AUTOSAR XML (schema 4-2-2)
package /COM_SWC
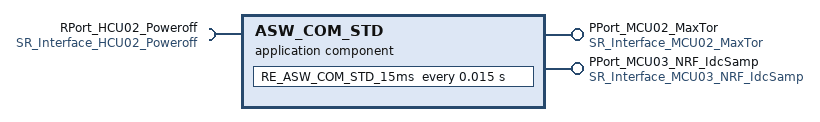
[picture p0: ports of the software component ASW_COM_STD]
  application sw component type ASW_COM_STD
    provide port PPort_MCU02_MaxTor: provided-interface=SR_Interface_MCU02_MaxTor
    provide port PPort_MCU03_NRF_IdcSamp: provided-interface=SR_Interface_MCU03_NRF_IdcSamp
    require port RPort_HCU02_Poweroff: nonqueued-receiver-com-spec{alive-timeout=0.3, data-element=HCU02_Poweroff}, required-interface=SR_Interface_HCU02_Poweroff
    behavior IB_ASW_COM_STD
      timing event TE_15ms_RE_ASW_COM_STD: start-on-event=RE_ASW_COM_STD_15ms, period=0.015
      runnable RE_ASW_COM_STD_15ms
